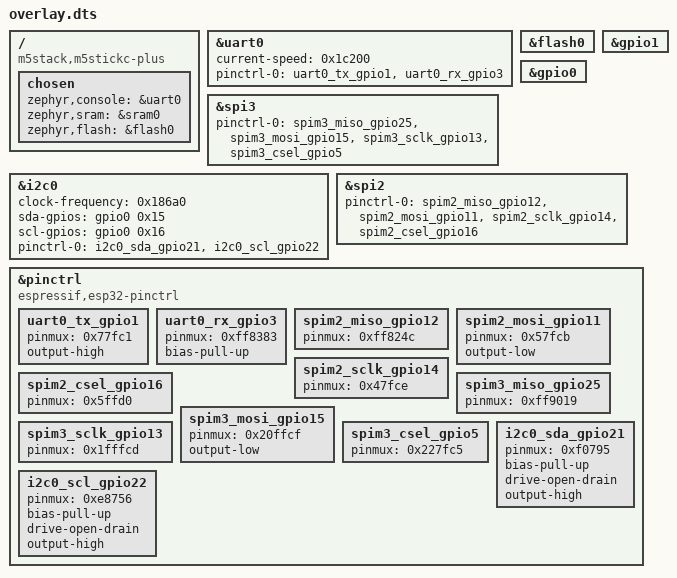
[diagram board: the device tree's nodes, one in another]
/ {
	compatible = "m5stack,m5stickc-plus";
	chosen {
		zephyr,console = &uart0;
		zephyr,sram = &sram0;
		zephyr,flash = &flash0;
	};
};
&uart0{
	status = "okay";
	current-speed = < 0x1c200 >;
	pinctrl-0 = < &uart0_tx_gpio1 &uart0_rx_gpio3 >;
	pinctrl-names = "default";
};
&spi3{
	status = "okay";
	#address-cells = < 0x1 >;
	#size-cells = < 0x0 >;
	pinctrl-0 = < &spim3_miso_gpio25 &spim3_mosi_gpio15 &spim3_sclk_gpio13 &spim3_csel_gpio5 >;
	pinctrl-names = "default";
};
&flash0{
	status = "okay";
};
&i2c0{
	status = "okay";
	clock-frequency = < 0x186a0 >;
	sda-gpios = < &gpio0 0x15 0x6 >;
	scl-gpios = < &gpio0 0x16 0x6 >;
	pinctrl-0 = < &i2c0_sda_gpio21 &i2c0_scl_gpio22 >;
	pinctrl-names = "default";
};
&gpio1{
	status = "okay";
};
&gpio0{
	status = "okay";
};
&spi2{
	status = "okay";
	#address-cells = < 0x1 >;
	#size-cells = < 0x0 >;
	pinctrl-0 = < &spim2_miso_gpio12 &spim2_mosi_gpio11 &spim2_sclk_gpio14 &spim2_csel_gpio16 >;
	pinctrl-names = "default";
};
&pinctrl{
	compatible = "espressif,esp32-pinctrl";
	status = "okay";
	uart0_tx_gpio1: uart0_tx_gpio1 {
		pinmux = < 0x77fc1 >;
		output-high;
	};
	uart0_rx_gpio3: uart0_rx_gpio3 {
		pinmux = < 0xff8383 >;
		bias-pull-up;
	};
	spim2_miso_gpio12: spim2_miso_gpio12 {
		pinmux = < 0xff824c >;
	};
	spim2_mosi_gpio11: spim2_mosi_gpio11 {
		pinmux = < 0x57fcb >;
		output-low;
	};
	spim2_sclk_gpio14: spim2_sclk_gpio14 {
		pinmux = < 0x47fce >;
	};
	spim2_csel_gpio16: spim2_csel_gpio16 {
		pinmux = < 0x5ffd0 >;
	};
	spim3_miso_gpio25: spim3_miso_gpio25 {
		pinmux = < 0xff9019 >;
	};
	spim3_mosi_gpio15: spim3_mosi_gpio15 {
		pinmux = < 0x20ffcf >;
		output-low;
	};
	spim3_sclk_gpio13: spim3_sclk_gpio13 {
		pinmux = < 0x1fffcd >;
	};
	spim3_csel_gpio5: spim3_csel_gpio5 {
		pinmux = < 0x227fc5 >;
	};
	i2c0_sda_gpio21: i2c0_sda_gpio21 {
		pinmux = < 0xf0795 >;
		bias-pull-up;
		drive-open-drain;
		output-high;
	};
	i2c0_scl_gpio22: i2c0_scl_gpio22 {
		pinmux = < 0xe8756 >;
		bias-pull-up;
		drive-open-drain;
		output-high;
	};
};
